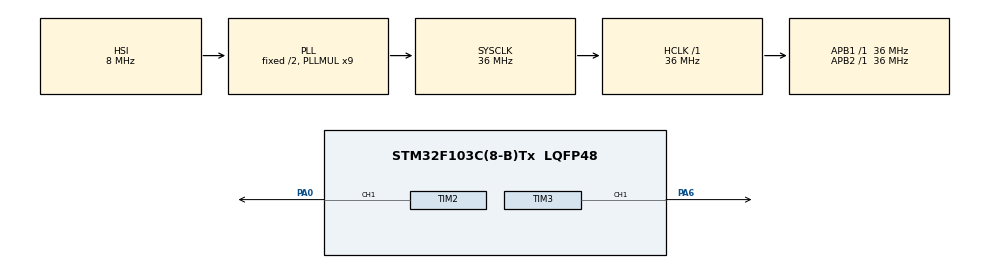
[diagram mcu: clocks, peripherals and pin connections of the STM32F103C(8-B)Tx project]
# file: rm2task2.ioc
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Mcu.Family=STM32F1
Mcu.Name=STM32F103C(8-B)Tx
Mcu.Package=LQFP48
NVIC.PriorityGroup=NVIC_PRIORITYGROUP_4
NVIC.TIM3_IRQn=true\:0\:0\:false\:false\:true\:true\:true\:true
NVIC.TIM4_IRQn=true\:0\:0\:false\:false\:true\:true\:true\:true
PA0-WKUP.Signal=S_TIM2_CH1_ETR
PA13.Mode=Serial_Wire
PA13.Signal=SYS_JTMS-SWDIO
PA14.Mode=Serial_Wire
PA14.Signal=SYS_JTCK-SWCLK
PA6.Signal=S_TIM3_CH1
ProjectManager.HeapSize=0x200
ProjectManager.StackSize=0x400
ProjectManager.TargetToolchain=CMake
RCC.AHBFreq_Value=36000000
RCC.APB1Freq_Value=36000000
RCC.APB1TimFreq_Value=36000000
RCC.APB2Freq_Value=36000000
RCC.APB2TimFreq_Value=36000000
RCC.HCLKFreq_Value=36000000
RCC.PLLMUL=RCC_PLL_MUL9
RCC.SYSCLKFreq_VALUE=36000000
RCC.SYSCLKSource=RCC_SYSCLKSOURCE_PLLCLK
RCC.USBFreq_Value=36000000
SH.S_TIM2_CH1_ETR.0=TIM2_CH1,PWM Generation1 CH1
SH.S_TIM3_CH1.0=TIM3_CH1,PWM Generation1 CH1
TIM2.AutoReloadPreload=TIM_AUTORELOAD_PRELOAD_ENABLE
TIM2.Channel-PWM\ Generation1\ CH1=TIM_CHANNEL_1
TIM2.Period=999
TIM2.Prescaler=35
TIM3.AutoReloadPreload=TIM_AUTORELOAD_PRELOAD_ENABLE
TIM3.Channel-PWM\ Generation1\ CH1=TIM_CHANNEL_1
TIM3.Period=19999
TIM3.Prescaler=35
TIM3.Pulse-PWM\ Generation1\ CH1=1500
TIM4.AutoReloadPreload=TIM_AUTORELOAD_PRELOAD_ENABLE
TIM4.Period=199
TIM4.Prescaler=3599
VP_TIM2_VS_ClockSourceINT.Mode=Internal
VP_TIM3_VS_ClockSourceINT.Mode=Internal
VP_TIM4_VS_ClockSourceINT.Mode=Internal
board=custom

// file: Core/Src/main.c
/* USER CODE BEGIN Header */
/**
  ******************************************************************************
  * @file           : main.c
  * @brief          : Main program body
  ******************************************************************************
  * @attention
  *
  * Copyright (c) 2026 STMicroelectronics.
  * All rights reserved.
  *
  * This software is licensed under terms that can be found in the LICENSE file
  * in the root directory of this software component.
  * If no LICENSE file comes with this software, it is provided AS-IS.
  *
  ******************************************************************************
  */
/* USER CODE END Header */
#include "main.h"

#include <time.h>

/* USER CODE BEGIN PM*/
/* USER CODE END PM */

TIM_HandleTypeDef htim2;
TIM_HandleTypeDef htim3;
TIM_HandleTypeDef htim4;

/* USER CODE BEGIN PV */
uint32_t bit=0;//此处为了满足呼吸灯亮度和舵机转动调整，引入bit作为tim4触发次数标志，可以做到周期性变化
uint8_t light=0;//未处理的light值
uint16_t CCR_light=0;//正式处理为ccr的light值
uint8_t du=0;
uint16_t CCR_du=0;//同上
/* USER CODE END PV */

void SystemClock_Config(void);
static void MX_GPIO_Init(void);
static void MX_TIM2_Init(void);
static void MX_TIM3_Init(void);
static void MX_TIM4_Init(void);

int main(void)
{

  /* MCU Configuration--------------------------------------------------------*/

  /* Reset of all peripherals, Initializes the Flash interface and the Systick. */
  HAL_Init();

  /* Configure the system clock */
  SystemClock_Config();

  /* Initialize all configured peripherals */
  MX_GPIO_Init();
  MX_TIM2_Init();
  MX_TIM3_Init();
  MX_TIM4_Init();
  /* USER CODE BEGIN 2 */
  HAL_TIM_PWM_Start(&htim2, TIM_CHANNEL_1);
  HAL_TIM_PWM_Start(&htim3, TIM_CHANNEL_1);
  HAL_TIM_Base_Start_IT(&htim4);
            /*此处采用TIM4作为状态机轮询，每20ms触发一次，既可以控制led的占空比，又可以控制舵机50hz的转动*/
  /* USER CODE END 2 */

  /* Infinite loop */
  while (1)
  {

  }
}

void SystemClock_Config(void)
{
  RCC_OscInitTypeDef RCC_OscInitStruct = {0};
  RCC_ClkInitTypeDef RCC_ClkInitStruct = {0};

  /** Initializes the RCC Oscillators according to the specified parameters
  * in the RCC_OscInitTypeDef structure.
  */
  RCC_OscInitStruct.OscillatorType = RCC_OSCILLATORTYPE_HSI;
  RCC_OscInitStruct.HSIState = RCC_HSI_ON;
  RCC_OscInitStruct.HSICalibrationValue = RCC_HSICALIBRATION_DEFAULT;
  RCC_OscInitStruct.PLL.PLLState = RCC_PLL_ON;
  RCC_OscInitStruct.PLL.PLLSource = RCC_PLLSOURCE_HSI_DIV2;
  RCC_OscInitStruct.PLL.PLLMUL = RCC_PLL_MUL9;
  if (HAL_RCC_OscConfig(&RCC_OscInitStruct) != HAL_OK)
  {
    Error_Handler();
  }

  /** Initializes the CPU, AHB and APB buses clocks
  */
  RCC_ClkInitStruct.ClockType = RCC_CLOCKTYPE_HCLK|RCC_CLOCKTYPE_SYSCLK
                              |RCC_CLOCKTYPE_PCLK1|RCC_CLOCKTYPE_PCLK2;
  RCC_ClkInitStruct.SYSCLKSource = RCC_SYSCLKSOURCE_PLLCLK;
  RCC_ClkInitStruct.AHBCLKDivider = RCC_SYSCLK_DIV1;
  RCC_ClkInitStruct.APB1CLKDivider = RCC_HCLK_DIV1;
  RCC_ClkInitStruct.APB2CLKDivider = RCC_HCLK_DIV1;

  if (HAL_RCC_ClockConfig(&RCC_ClkInitStruct, FLASH_LATENCY_1) != HAL_OK)
  {
    Error_Handler();
  }
}

static void MX_TIM2_Init(void)
{

  TIM_ClockConfigTypeDef sClockSourceConfig = {0};
  TIM_MasterConfigTypeDef sMasterConfig = {0};
  TIM_OC_InitTypeDef sConfigOC = {0};

  htim2.Instance = TIM2;
  htim2.Init.Prescaler = 35;
  htim2.Init.CounterMode = TIM_COUNTERMODE_UP;
  htim2.Init.Period = 999;
  htim2.Init.ClockDivision = TIM_CLOCKDIVISION_DIV1;
  htim2.Init.AutoReloadPreload = TIM_AUTORELOAD_PRELOAD_ENABLE;
  if (HAL_TIM_Base_Init(&htim2) != HAL_OK)
  {
    Error_Handler();
  }
  sClockSourceConfig.ClockSource = TIM_CLOCKSOURCE_INTERNAL;
  if (HAL_TIM_ConfigClockSource(&htim2, &sClockSourceConfig) != HAL_OK)
  {
    Error_Handler();
  }
  if (HAL_TIM_PWM_Init(&htim2) != HAL_OK)
  {
    Error_Handler();
  }
  sMasterConfig.MasterOutputTrigger = TIM_TRGO_RESET;
  sMasterConfig.MasterSlaveMode = TIM_MASTERSLAVEMODE_DISABLE;
  if (HAL_TIMEx_MasterConfigSynchronization(&htim2, &sMasterConfig) != HAL_OK)
  {
    Error_Handler();
  }
  sConfigOC.OCMode = TIM_OCMODE_PWM1;
  sConfigOC.Pulse = 0;
  sConfigOC.OCPolarity = TIM_OCPOLARITY_HIGH;
  sConfigOC.OCFastMode = TIM_OCFAST_DISABLE;
  if (HAL_TIM_PWM_ConfigChannel(&htim2, &sConfigOC, TIM_CHANNEL_1) != HAL_OK)
  {
    Error_Handler();
  }
  HAL_TIM_MspPostInit(&htim2);

}

static void MX_TIM3_Init(void)
{

  TIM_ClockConfigTypeDef sClockSourceConfig = {0};
  TIM_MasterConfigTypeDef sMasterConfig = {0};
  TIM_OC_InitTypeDef sConfigOC = {0};

  htim3.Instance = TIM3;
  htim3.Init.Prescaler = 35;
  htim3.Init.CounterMode = TIM_COUNTERMODE_UP;
  htim3.Init.Period = 19999;
  htim3.Init.ClockDivision = TIM_CLOCKDIVISION_DIV1;
  htim3.Init.AutoReloadPreload = TIM_AUTORELOAD_PRELOAD_ENABLE;
  if (HAL_TIM_Base_Init(&htim3) != HAL_OK)
  {
    Error_Handler();
  }
  sClockSourceConfig.ClockSource = TIM_CLOCKSOURCE_INTERNAL;
  if (HAL_TIM_ConfigClockSource(&htim3, &sClockSourceConfig) != HAL_OK)
  {
    Error_Handler();
  }
  if (HAL_TIM_PWM_Init(&htim3) != HAL_OK)
  {
    Error_Handler();
  }
  sMasterConfig.MasterOutputTrigger = TIM_TRGO_RESET;
  sMasterConfig.MasterSlaveMode = TIM_MASTERSLAVEMODE_DISABLE;
  if (HAL_TIMEx_MasterConfigSynchronization(&htim3, &sMasterConfig) != HAL_OK)
  {
    Error_Handler();
  }
  sConfigOC.OCMode = TIM_OCMODE_PWM1;
  sConfigOC.Pulse = 1500;
  sConfigOC.OCPolarity = TIM_OCPOLARITY_HIGH;
  sConfigOC.OCFastMode = TIM_OCFAST_DISABLE;
  if (HAL_TIM_PWM_ConfigChannel(&htim3, &sConfigOC, TIM_CHANNEL_1) != HAL_OK)
  {
    Error_Handler();
  }
  HAL_TIM_MspPostInit(&htim3);

}

static void MX_TIM4_Init(void)
{

  TIM_ClockConfigTypeDef sClockSourceConfig = {0};
  TIM_MasterConfigTypeDef sMasterConfig = {0};

  htim4.Instance = TIM4;
  htim4.Init.Prescaler = 3599;
  htim4.Init.CounterMode = TIM_COUNTERMODE_UP;
  htim4.Init.Period = 199;
  htim4.Init.ClockDivision = TIM_CLOCKDIVISION_DIV1;
  htim4.Init.AutoReloadPreload = TIM_AUTORELOAD_PRELOAD_ENABLE;
  if (HAL_TIM_Base_Init(&htim4) != HAL_OK)
  {
    Error_Handler();
  }
  sClockSourceConfig.ClockSource = TIM_CLOCKSOURCE_INTERNAL;
  if (HAL_TIM_ConfigClockSource(&htim4, &sClockSourceConfig) != HAL_OK)
  {
    Error_Handler();
  }
  sMasterConfig.MasterOutputTrigger = TIM_TRGO_RESET;
  sMasterConfig.MasterSlaveMode = TIM_MASTERSLAVEMODE_DISABLE;
  if (HAL_TIMEx_MasterConfigSynchronization(&htim4, &sMasterConfig) != HAL_OK)
  {
    Error_Handler();
  }

}

static void MX_GPIO_Init(void)
{

  /* GPIO Ports Clock Enable */
  __HAL_RCC_GPIOA_CLK_ENABLE();

}

/* USER CODE BEGIN 4 */
void HAL_TIM_PeriodElapsedCallback(TIM_HandleTypeDef *htim)
{
  if (htim->Instance==TIM4)
  {
    bit++;//正常来说，bit应该是满100就变成0，满50亮度倒退，但学习三角波之后可以对其取余，不用重置
    light=bit%100;
    if (light>=0 && light<50)
      CCR_light=light*20;//arr为999，ccr能在1s内从0到1000即可，tim4会经历50次溢出
    else
      CCR_light=2000-light*20;
    __HAL_TIM_SET_COMPARE(&htim2, TIM_CHANNEL_1, CCR_light);
    /*ok啊，现在是舵机环节，tim4频率也是50hz，bit在舵机这里也是通用的*/
    du=bit%200;//周期为4s
    if (du>=0 && du<100)
      CCR_du=500+20*du;
    else
      CCR_du=2500-20*(du-100);
    __HAL_TIM_SET_COMPARE(&htim3, TIM_CHANNEL_1, CCR_du);
  }
}
/* USER CODE END 4 */

void Error_Handler(void)
{
  __disable_irq();
  while (1)
  {
  }
}
